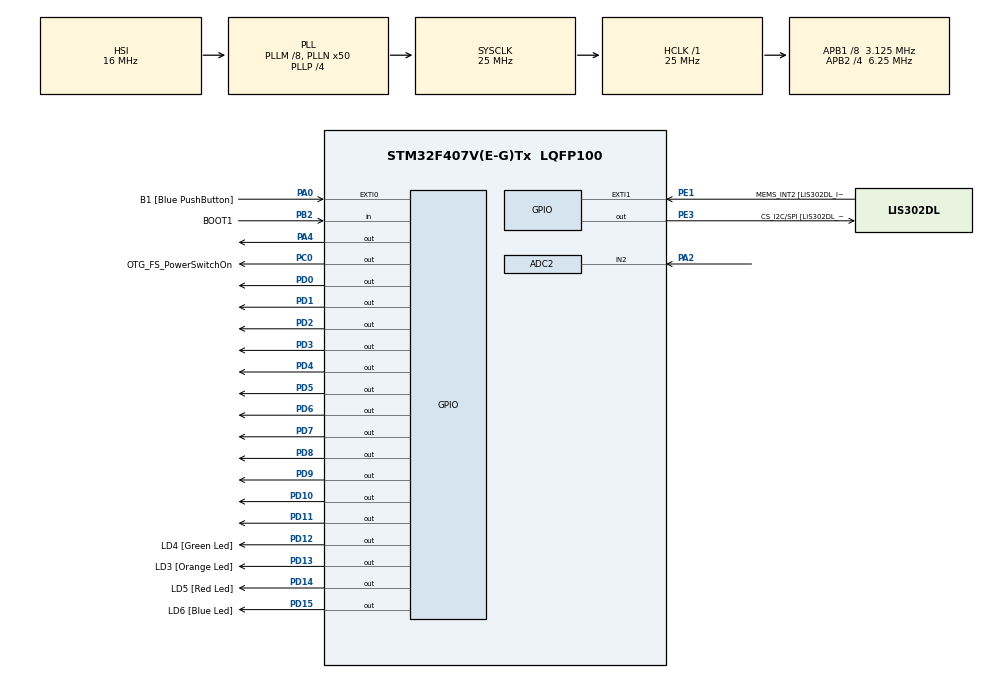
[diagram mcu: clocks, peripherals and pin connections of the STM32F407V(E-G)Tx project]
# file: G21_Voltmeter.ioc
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ADC2.Channel-0\#ChannelRegularConversion=ADC_CHANNEL_2
ADC2.ClockPrescaler=ADC_CLOCK_SYNC_PCLK_DIV2
ADC2.ContinuousConvMode=DISABLE
ADC2.DMAContinuousRequests=DISABLE
ADC2.DataAlign=ADC_DATAALIGN_RIGHT
ADC2.DiscontinuousConvMode=DISABLE
ADC2.EOCSelection=ADC_EOC_SINGLE_CONV
ADC2.EnableAnalogWatchDog=false
ADC2.ExternalTrigConv=ADC_EXTERNALTRIGCONV_T2_TRGO
ADC2.ExternalTrigConvEdge=ADC_EXTERNALTRIGCONVEDGE_RISING
ADC2.InjNumberOfConversion=0
ADC2.NbrOfConversion=1
ADC2.NbrOfConversionFlag=1
ADC2.Rank-0\#ChannelRegularConversion=1
ADC2.Resolution=ADC_RESOLUTION_8B
ADC2.SamplingTime-0\#ChannelRegularConversion=ADC_SAMPLETIME_3CYCLES
ADC2.ScanConvMode=DISABLE
Mcu.Family=STM32F4
Mcu.Name=STM32F407V(E-G)Tx
Mcu.Package=LQFP100
NVIC.ADC_IRQn=true\:0\:0\:false\:false\:true\:true
NVIC.PriorityGroup=NVIC_PRIORITYGROUP_0
NVIC.TIM2_IRQn=true\:0\:0\:false\:false\:true\:true
NVIC.TIM3_IRQn=true\:0\:0\:false\:false\:true\:true
PA0-WKUP.GPIO_Label=B1 [Blue PushButton]
PA0-WKUP.GPIO_ModeDefaultEXTI=GPIO_MODE_EVT_RISING
PA0-WKUP.GPIO_PuPd=GPIO_NOPULL
PA0-WKUP.Signal=GPXTI0
PA10.GPIO_Label=OTG_FS_ID
PA10.GPIO_Mode=GPIO_MODE_AF_PP
PA10.GPIO_PuPd=GPIO_NOPULL
PA10.GPIO_Speed=GPIO_SPEED_FREQ_LOW
PA10.Signal=USB_OTG_FS_ID
PA11.GPIO_Label=OTG_FS_DM
PA11.GPIO_Mode=GPIO_MODE_AF_PP
PA11.GPIO_PuPd=GPIO_NOPULL
PA11.GPIO_Speed=GPIO_SPEED_FREQ_LOW
PA11.Signal=USB_OTG_FS_DM
PA12.GPIO_Label=OTG_FS_DP
PA12.GPIO_Mode=GPIO_MODE_AF_PP
PA12.GPIO_PuPd=GPIO_NOPULL
PA12.GPIO_Speed=GPIO_SPEED_FREQ_LOW
PA12.Signal=USB_OTG_FS_DP
PA13.GPIO_Label=SWDIO
PA13.Signal=SYS_JTMS-SWDIO
PA14.GPIO_Label=SWCLK
PA14.Signal=SYS_JTCK-SWCLK
PA2.Signal=ADCx_IN2
PA4.Signal=GPIO_Output
PA5.GPIO_Label=SPI1_SCK [LIS302DL_SCL/SPC]
PA5.GPIO_Mode=GPIO_MODE_AF_PP
PA5.GPIO_PuPd=GPIO_NOPULL
PA5.GPIO_Speed=GPIO_SPEED_FREQ_LOW
PA5.Signal=SPI1_SCK
PA6.GPIO_Label=SPI1_MISO [LIS302DL_SDO]
PA6.GPIO_Mode=GPIO_MODE_AF_PP
PA6.GPIO_PuPd=GPIO_NOPULL
PA6.GPIO_Speed=GPIO_SPEED_FREQ_LOW
PA6.Signal=SPI1_MISO
PA7.GPIO_Label=SPI1_MOSI [LIS302DL_SDA/SDI/SDO]
PA7.GPIO_Mode=GPIO_MODE_AF_PP
PA7.GPIO_PuPd=GPIO_NOPULL
PA7.GPIO_Speed=GPIO_SPEED_FREQ_LOW
PA7.Signal=SPI1_MOSI
PA9.GPIO_Label=VBUS_FS
PA9.GPIO_Mode=GPIO_MODE_INPUT
PA9.GPIO_PuPd=GPIO_NOPULL
PA9.Signal=USB_OTG_FS_VBUS
PB10.GPIO_Label=CLK_IN [MP45DT02_CLK]
PB10.GPIO_Mode=GPIO_MODE_AF_PP
PB10.GPIO_PuPd=GPIO_NOPULL
PB10.GPIO_Speed=GPIO_SPEED_FREQ_LOW
PB10.Signal=I2S2_CK
PB2.GPIO_Label=BOOT1
PB2.GPIO_Mode=GPIO_MODE_INPUT
PB2.GPIO_PuPd=GPIO_NOPULL
PB2.Signal=GPIO_Input
PB3.GPIO_Label=SWO
PB3.Signal=SYS_JTDO-SWO
PB6.GPIO_Label=Audio_SCL [CS43L22_SCL]
PB6.GPIO_Mode=GPIO_MODE_AF_OD
PB6.GPIO_PuPd=GPIO_NOPULL
PB6.GPIO_Speed=GPIO_SPEED_FREQ_LOW
PB6.Signal=I2C1_SCL
PB9.GPIO_Label=Audio_SDA [CS43L22_SDA]
PB9.GPIO_Mode=GPIO_MODE_AF_OD
PB9.GPIO_PuPd=GPIO_NOPULL
PB9.GPIO_Speed=GPIO_SPEED_FREQ_LOW
PB9.Signal=I2C1_SDA
PC0.GPIO_Label=OTG_FS_PowerSwitchOn
PC0.GPIO_PuPd=GPIO_NOPULL
PC0.GPIO_Speed=GPIO_SPEED_FREQ_LOW
PC0.PinState=GPIO_PIN_SET
PC0.Signal=GPIO_Output
PC10.GPIO_Label=I2S3_SCK [CS43L22_SCLK]
PC10.GPIO_Mode=GPIO_MODE_AF_PP
PC10.GPIO_PuPd=GPIO_NOPULL
PC10.GPIO_Speed=GPIO_SPEED_FREQ_LOW
PC10.Signal=I2S3_CK
PC12.GPIO_Label=I2S3_SD [CS43L22_SDIN]
PC12.GPIO_Mode=GPIO_MODE_AF_PP
PC12.GPIO_PuPd=GPIO_NOPULL
PC12.GPIO_Speed=GPIO_SPEED_FREQ_LOW
PC12.Signal=I2S3_SD
PC14-OSC32_IN.GPIO_Label=PC14-OSC32_IN
PC14-OSC32_IN.Signal=RCC_OSC32_IN
PC15-OSC32_OUT.GPIO_Label=PC15-OSC32_OUT
PC15-OSC32_OUT.Signal=RCC_OSC32_OUT
PC3.GPIO_Label=PDM_OUT [MP45DT02_DOUT]
PC3.GPIO_Mode=GPIO_MODE_AF_PP
PC3.GPIO_PuPd=GPIO_NOPULL
PC3.GPIO_Speed=GPIO_SPEED_FREQ_LOW
PC3.Signal=I2S2_SD
PC7.GPIO_Label=I2S3_MCK [CS43L22_MCLK]
PC7.GPIO_Mode=GPIO_MODE_AF_PP
PC7.GPIO_PuPd=GPIO_NOPULL
PC7.GPIO_Speed=GPIO_SPEED_FREQ_LOW
PC7.Signal=I2S3_MCK
PD0.Signal=GPIO_Output
PD1.Signal=GPIO_Output
PD10.Signal=GPIO_Output
PD11.Signal=GPIO_Output
PD12.GPIO_Label=LD4 [Green Led]
PD12.GPIO_PuPd=GPIO_NOPULL
PD12.GPIO_Speed=GPIO_SPEED_FREQ_LOW
PD12.Signal=GPIO_Output
PD13.GPIO_Label=LD3 [Orange Led]
PD13.GPIO_PuPd=GPIO_NOPULL
PD13.GPIO_Speed=GPIO_SPEED_FREQ_LOW
PD13.Signal=GPIO_Output
PD14.GPIO_Label=LD5 [Red Led]
PD14.GPIO_PuPd=GPIO_NOPULL
PD14.GPIO_Speed=GPIO_SPEED_FREQ_LOW
PD14.Signal=GPIO_Output
PD15.GPIO_Label=LD6 [Blue Led]
PD15.GPIO_PuPd=GPIO_NOPULL
PD15.GPIO_Speed=GPIO_SPEED_FREQ_LOW
PD15.Signal=GPIO_Output
PD2.Signal=GPIO_Output
PD3.Signal=GPIO_Output
PD4.Signal=GPIO_Output
PD5.Signal=GPIO_Output
PD6.Signal=GPIO_Output
PD7.Signal=GPIO_Output
PD8.Signal=GPIO_Output
PD9.Signal=GPIO_Output
PE1.GPIO_Label=MEMS_INT2 [LIS302DL_INT2]
PE1.GPIO_ModeDefaultEXTI=GPIO_MODE_EVT_RISING
PE1.GPIO_PuPd=GPIO_NOPULL
PE1.Signal=GPXTI1
PE3.GPIO_Label=CS_I2C/SPI [LIS302DL_CS_I2C/SPI]
PE3.GPIO_PuPd=GPIO_NOPULL
PE3.GPIO_Speed=GPIO_SPEED_FREQ_LOW
PE3.Signal=GPIO_Output
PH0-OSC_IN.GPIO_Label=PH0-OSC_IN
PH0-OSC_IN.Signal=RCC_OSC_IN
PH1-OSC_OUT.GPIO_Label=PH1-OSC_OUT
PH1-OSC_OUT.Signal=RCC_OSC_OUT
ProjectManager.HeapSize=0x200
ProjectManager.StackSize=0x400
ProjectManager.TargetToolchain=MDK-ARM V5
RCC.48MHZClocksFreq_Value=14285714.285714285
RCC.AHBFreq_Value=25000000
RCC.APB1CLKDivider=RCC_HCLK_DIV8
RCC.APB1Freq_Value=3125000
RCC.APB1TimFreq_Value=6250000
RCC.APB2CLKDivider=RCC_HCLK_DIV4
RCC.APB2Freq_Value=6250000
RCC.APB2TimFreq_Value=12500000
RCC.CortexFreq_Value=25000000
RCC.HCLKFreq_Value=25000000
RCC.HSE_VALUE=8000000
RCC.HSI_VALUE=16000000
RCC.LSE_VALUE=32768
RCC.PLLM=8
RCC.PLLN=50
RCC.PLLP=RCC_PLLP_DIV4
RCC.PLLQ=7
RCC.SYSCLKFreq_VALUE=25000000
RCC.SYSCLKSource=RCC_SYSCLKSOURCE_PLLCLK
RCC.VCOOutputFreq_Value=100000000
SH.ADCx_IN2.0=ADC2_IN2,IN2
TIM2.Period=10
TIM2.Prescaler=625
TIM2.TIM_MasterOutputTrigger=TIM_TRGO_UPDATE
TIM3.Period=100
TIM3.Prescaler=625
TIM3.TIM_MasterOutputTrigger=TIM_TRGO_UPDATE
VP_TIM2_VS_ClockSourceINT.Mode=Internal
VP_TIM3_VS_ClockSourceINT.Mode=Internal
board=STM32F4DISCOVERY

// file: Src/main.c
/**
  ******************************************************************************
  * File Name          : main.c
  * Description        : Main program body
  ******************************************************************************
  ** This notice applies to any and all portions of this file
  * that are not between comment pairs USER CODE BEGIN and
  * USER CODE END. Other portions of this file, whether
  * inserted by the user or by software development tools
  * are owned by their respective copyright owners.
  *
  * COPYRIGHT(c) 2017 STMicroelectronics
  *
  * Redistribution and use in source and binary forms, with or without modification,
  * are permitted provided that the following conditions are met:
  *   1. Redistributions of source code must retain the above copyright notice,
  *      this list of conditions and the following disclaimer.
  *   2. Redistributions in binary form must reproduce the above copyright notice,
  *      this list of conditions and the following disclaimer in the documentation
  *      and/or other materials provided with the distribution.
  *   3. Neither the name of STMicroelectronics nor the names of its contributors
  *      may be used to endorse or promote products derived from this software
  *      without specific prior written permission.
  *
  * THIS SOFTWARE IS PROVIDED BY THE COPYRIGHT HOLDERS AND CONTRIBUTORS "AS IS"
  * AND ANY EXPRESS OR IMPLIED WARRANTIES, INCLUDING, BUT NOT LIMITED TO, THE
  * IMPLIED WARRANTIES OF MERCHANTABILITY AND FITNESS FOR A PARTICULAR PURPOSE ARE
  * DISCLAIMED. IN NO EVENT SHALL THE COPYRIGHT HOLDER OR CONTRIBUTORS BE LIABLE
  * FOR ANY DIRECT, INDIRECT, INCIDENTAL, SPECIAL, EXEMPLARY, OR CONSEQUENTIAL
  * DAMAGES (INCLUDING, BUT NOT LIMITED TO, PROCUREMENT OF SUBSTITUTE GOODS OR
  * SERVICES; LOSS OF USE, DATA, OR PROFITS; OR BUSINESS INTERRUPTION) HOWEVER
  * CAUSED AND ON ANY THEORY OF LIABILITY, WHETHER IN CONTRACT, STRICT LIABILITY,
  * OR TORT (INCLUDING NEGLIGENCE OR OTHERWISE) ARISING IN ANY WAY OUT OF THE USE
  * OF THIS SOFTWARE, EVEN IF ADVISED OF THE POSSIBILITY OF SUCH DAMAGE.
  *
  ******************************************************************************
  */
#include "main.h"
#include "stm32f4xx_hal.h"

/* USER CODE BEGIN Includes */
#include "math.h"
#include "float.h"
/* USER CODE END Includes */

ADC_HandleTypeDef hadc2;

TIM_HandleTypeDef htim2;
TIM_HandleTypeDef htim3;

/* USER CODE BEGIN PV */
/* Private variables ---------------------------------------------------------*/

/* USER CODE END PV */

void SystemClock_Config(void);
static void MX_GPIO_Init(void);
static void MX_ADC2_Init(void);
static void MX_TIM3_Init(void);
static void MX_TIM2_Init(void);

/* USER CODE BEGIN PFP */
/* Private function prototypes -----------------------------------------------*/
void numControl(int num, int D);
void FloatToIntArr(float num);
/* USER CODE END PFP */

/* USER CODE GLOBAL VARs */
const int N = 10;	//window size
const float SYS_VOLT = 2.98;	//system voltage
const int COUNT_MAX = 1;	//delay in displaying

float valA = 0, valB = 0;
unsigned int adcVal;	//stores sample form ADC
float volt;	//stores voltage conversion
float Vrms;	//stores Vrms value
int counter;//to generate a square wave of 1/counter Hz
int k = 1;	//before N samples
int D[4];		//stores numbers to be displayed
float buff[N];//stores inst voltages
/* USER CODE END GLOBAL VARs */

int main(void)
{

  /* MCU Configuration----------------------------------------------------------*/

  /* Reset of all peripherals, Initializes the Flash interface and the Systick. */
  HAL_Init();

  /* Configure the system clock */
  SystemClock_Config();

  /* Initialize all configured peripherals */
  MX_GPIO_Init();
  MX_ADC2_Init();
  MX_TIM3_Init();
  MX_TIM2_Init();

	/* Start Timer as interrupt */
	HAL_TIM_Base_Start_IT(&htim2);
	HAL_TIM_Base_Start_IT(&htim3);

	/* Start ADC */
	HAL_ADC_Start(&hadc2);

	/* USER CODE 7-SEGMENT DISPLAY */

	/*---PIN CONFIGURATION---
	GPIO_PIN_11 (PD11) <- D4 SET
	GPIO_PIN_10 (PD10) <- D3 SET
	GPIO_PIN_9 (PD9) <- D2  SET
	GPIO_PIN_8 (PD8) <- D1 SET

	GPIO_PIN_0 (PD0) <- A
	GPIO_PIN_1 (PD1) <- B
	GPIO_PIN_2 (PD2) <- C
	GPIO_PIN_3 (PD3) <- D
	GPIO_PIN_4 (PD4) <- E
	GPIO_PIN_5 (PD5) <- F
	GPIO_PIN_6 (PD6) <- G
	GPIO_PIN_7 (PD7) <- DP
	*/
  while (1)
  {
		/* converts from float to int[]
			 D[0] <- num in D1
			 D[1] <- num in D2
			 D[2] <- num in D3
			 D[3] <- num in D4
		*/

		FloatToIntArr(Vrms);

		while(counter != COUNT_MAX) {
			for(int i = 0; i < 4; i++) {	//Display
				numControl(D[i], i);
				HAL_Delay(1);
			}
			if(counter > COUNT_MAX) counter = 0;
		}

  }

	/* USER CODE END */

}

/* ISR HANDLER(EVERY 1ms) DO:
	 1. ADC sample
	 2. Overhead(conversion+updating+calculation)
	 3. checks*/
void HAL_TIM_PeriodElapsedCallback(TIM_HandleTypeDef *htim) {
	if(htim == &htim2) {	//ADC sampling
		/*
		range: 0 to 255 (8 bits)
		Sysyem voltage = 2.98V

		Measured voltage = (System voltage * adcVal)/255
		*/

		adcVal = HAL_ADC_GetValue(&hadc2);	//take a sample

		//convert ADC to Voltage
		volt = (adcVal*SYS_VOLT)/255;

		//update valA and valB
		valA += volt*volt;
		valB += (buff[0]*buff[0]);

		if(valA > FLT_MAX-20){	//overflow handler
			valA = valA-valB;
			valB = 0;
		}

		if(k < N) {	//takes care or first N samples
			Vrms = sqrt(valA/k);
			k++;
		} else {
			Vrms = sqrt((valA-valB)/N);
		}

		//update buffer
		for(int i = 0; i < N-1; i++) {
			buff[i] = buff[i+1];
		}
		buff[N-1] = volt;
	}

	else if(htim == &htim3) {	//AC square signal(50Hz)
		counter++;
		HAL_GPIO_TogglePin(GPIOA, GPIO_PIN_4);
	}

}

/* USER HELPER FUNCTIONS*/

/* Sets a digit (of the 7-segment display),
	 and the corresponding segments */
void numControl(int num, int D) {
	/* Truth table of numbers 0-9
			NUM		A	B	C	D	E	F	G

				0		1	1	1	1	1	1	0

				1		0	1	1	0	0	0	0

				2		1	1	0	1	1	0	1

				3		1	1	1	1	0	0	1

				4		0	1	1	0	0	1	1

				5		1	0	1	1	0	1	1

				6		1	0	1	1	1	1	1

				7		1	1	1	0	0	0	0

				8		1	1	1	1	1	1	1

				9		1	1	1	1	0	1	1
	*/

	/*takes care of setting/resetting Ds
	  decimal point is set with D2 */
	if(D == 0) {
		HAL_GPIO_WritePin(GPIOD, GPIO_PIN_7, GPIO_PIN_RESET);
		HAL_GPIO_WritePin(GPIOD, GPIO_PIN_8, GPIO_PIN_RESET);
		HAL_GPIO_WritePin(GPIOD, GPIO_PIN_9, GPIO_PIN_RESET);
		HAL_GPIO_WritePin(GPIOD, GPIO_PIN_10, GPIO_PIN_RESET);
		HAL_GPIO_WritePin(GPIOD, GPIO_PIN_11, GPIO_PIN_RESET);
	}
	else if(D == 1) {
		HAL_GPIO_WritePin(GPIOD, GPIO_PIN_7, GPIO_PIN_SET);
		HAL_GPIO_WritePin(GPIOD, GPIO_PIN_8, GPIO_PIN_RESET);
		HAL_GPIO_WritePin(GPIOD, GPIO_PIN_9, GPIO_PIN_SET);
		HAL_GPIO_WritePin(GPIOD, GPIO_PIN_10, GPIO_PIN_RESET);
		HAL_GPIO_WritePin(GPIOD, GPIO_PIN_11, GPIO_PIN_RESET);
	}
	else if(D == 2) {
		HAL_GPIO_WritePin(GPIOD, GPIO_PIN_7, GPIO_PIN_RESET);
		HAL_GPIO_WritePin(GPIOD, GPIO_PIN_8, GPIO_PIN_RESET);
		HAL_GPIO_WritePin(GPIOD, GPIO_PIN_9, GPIO_PIN_RESET);
		HAL_GPIO_WritePin(GPIOD, GPIO_PIN_10, GPIO_PIN_SET);
		HAL_GPIO_WritePin(GPIOD, GPIO_PIN_11, GPIO_PIN_RESET);
	}
	else if(D == 3) {
		HAL_GPIO_WritePin(GPIOD, GPIO_PIN_7, GPIO_PIN_RESET);
		HAL_GPIO_WritePin(GPIOD, GPIO_PIN_8, GPIO_PIN_RESET);
		HAL_GPIO_WritePin(GPIOD, GPIO_PIN_9, GPIO_PIN_RESET);
		HAL_GPIO_WritePin(GPIOD, GPIO_PIN_10, GPIO_PIN_RESET);
		HAL_GPIO_WritePin(GPIOD, GPIO_PIN_11, GPIO_PIN_SET);
	}

	//takes care of displaying the required number (according to the truth table)
	if(num == 0) {
		HAL_GPIO_WritePin(GPIOD, GPIO_PIN_0, GPIO_PIN_SET);
		HAL_GPIO_WritePin(GPIOD, GPIO_PIN_1, GPIO_PIN_SET);
		HAL_GPIO_WritePin(GPIOD, GPIO_PIN_2, GPIO_PIN_SET);
		HAL_GPIO_WritePin(GPIOD, GPIO_PIN_3, GPIO_PIN_SET);
		HAL_GPIO_WritePin(GPIOD, GPIO_PIN_4, GPIO_PIN_SET);
		HAL_GPIO_WritePin(GPIOD, GPIO_PIN_5, GPIO_PIN_SET);
		HAL_GPIO_WritePin(GPIOD, GPIO_PIN_6, GPIO_PIN_RESET);
	} else if(num == 1) {
		HAL_GPIO_WritePin(GPIOD, GPIO_PIN_0, GPIO_PIN_RESET);
		HAL_GPIO_WritePin(GPIOD, GPIO_PIN_1, GPIO_PIN_SET);
		HAL_GPIO_WritePin(GPIOD, GPIO_PIN_2, GPIO_PIN_SET);
		HAL_GPIO_WritePin(GPIOD, GPIO_PIN_3, GPIO_PIN_RESET);
		HAL_GPIO_WritePin(GPIOD, GPIO_PIN_4, GPIO_PIN_RESET);
		HAL_GPIO_WritePin(GPIOD, GPIO_PIN_5, GPIO_PIN_RESET);
		HAL_GPIO_WritePin(GPIOD, GPIO_PIN_6, GPIO_PIN_RESET);
	} else if(num == 2) {
		HAL_GPIO_WritePin(GPIOD, GPIO_PIN_0, GPIO_PIN_SET);
		HAL_GPIO_WritePin(GPIOD, GPIO_PIN_1, GPIO_PIN_SET);
		HAL_GPIO_WritePin(GPIOD, GPIO_PIN_2, GPIO_PIN_RESET);
		HAL_GPIO_WritePin(GPIOD, GPIO_PIN_3, GPIO_PIN_SET);
		HAL_GPIO_WritePin(GPIOD, GPIO_PIN_4, GPIO_PIN_SET);
		HAL_GPIO_WritePin(GPIOD, GPIO_PIN_5, GPIO_PIN_RESET);
		HAL_GPIO_WritePin(GPIOD, GPIO_PIN_6, GPIO_PIN_SET);
	} else if(num == 3) {
		HAL_GPIO_WritePin(GPIOD, GPIO_PIN_0, GPIO_PIN_SET);
		HAL_GPIO_WritePin(GPIOD, GPIO_PIN_1, GPIO_PIN_SET);
		HAL_GPIO_WritePin(GPIOD, GPIO_PIN_2, GPIO_PIN_SET);
		HAL_GPIO_WritePin(GPIOD, GPIO_PIN_3, GPIO_PIN_SET);
		HAL_GPIO_WritePin(GPIOD, GPIO_PIN_4, GPIO_PIN_RESET);
		HAL_GPIO_WritePin(GPIOD, GPIO_PIN_5, GPIO_PIN_RESET);
		HAL_GPIO_WritePin(GPIOD, GPIO_PIN_6, GPIO_PIN_SET);
	} else if(num == 4) {
		HAL_GPIO_WritePin(GPIOD, GPIO_PIN_0, GPIO_PIN_RESET);
		HAL_GPIO_WritePin(GPIOD, GPIO_PIN_1, GPIO_PIN_SET);
		HAL_GPIO_WritePin(GPIOD, GPIO_PIN_2, GPIO_PIN_SET);
		HAL_GPIO_WritePin(GPIOD, GPIO_PIN_3, GPIO_PIN_RESET);
		HAL_GPIO_WritePin(GPIOD, GPIO_PIN_4, GPIO_PIN_RESET);
		HAL_GPIO_WritePin(GPIOD, GPIO_PIN_5, GPIO_PIN_SET);
		HAL_GPIO_WritePin(GPIOD, GPIO_PIN_6, GPIO_PIN_SET);
	} else if(num == 5) {
		HAL_GPIO_WritePin(GPIOD, GPIO_PIN_0, GPIO_PIN_SET);
		HAL_GPIO_WritePin(GPIOD, GPIO_PIN_1, GPIO_PIN_RESET);
		HAL_GPIO_WritePin(GPIOD, GPIO_PIN_2, GPIO_PIN_SET);
		HAL_GPIO_WritePin(GPIOD, GPIO_PIN_3, GPIO_PIN_SET);
		HAL_GPIO_WritePin(GPIOD, GPIO_PIN_4, GPIO_PIN_RESET);
		HAL_GPIO_WritePin(GPIOD, GPIO_PIN_5, GPIO_PIN_SET);
		HAL_GPIO_WritePin(GPIOD, GPIO_PIN_6, GPIO_PIN_SET);
	} else if(num == 6) {
		HAL_GPIO_WritePin(GPIOD, GPIO_PIN_0, GPIO_PIN_SET);
		HAL_GPIO_WritePin(GPIOD, GPIO_PIN_1, GPIO_PIN_RESET);
		HAL_GPIO_WritePin(GPIOD, GPIO_PIN_2, GPIO_PIN_SET);
		HAL_GPIO_WritePin(GPIOD, GPIO_PIN_3, GPIO_PIN_SET);
		HAL_GPIO_WritePin(GPIOD, GPIO_PIN_4, GPIO_PIN_SET);
		HAL_GPIO_WritePin(GPIOD, GPIO_PIN_5, GPIO_PIN_SET);
		HAL_GPIO_WritePin(GPIOD, GPIO_PIN_6, GPIO_PIN_SET);
	} else if(num == 7) {
		HAL_GPIO_WritePin(GPIOD, GPIO_PIN_0, GPIO_PIN_SET);
		HAL_GPIO_WritePin(GPIOD, GPIO_PIN_1, GPIO_PIN_SET);
		HAL_GPIO_WritePin(GPIOD, GPIO_PIN_2, GPIO_PIN_SET);
		HAL_GPIO_WritePin(GPIOD, GPIO_PIN_3, GPIO_PIN_RESET);
		HAL_GPIO_WritePin(GPIOD, GPIO_PIN_4, GPIO_PIN_RESET);
		HAL_GPIO_WritePin(GPIOD, GPIO_PIN_5, GPIO_PIN_RESET);
		HAL_GPIO_WritePin(GPIOD, GPIO_PIN_6, GPIO_PIN_RESET);
	} else if(num == 8) {
		HAL_GPIO_WritePin(GPIOD, GPIO_PIN_0, GPIO_PIN_SET);
		HAL_GPIO_WritePin(GPIOD, GPIO_PIN_1, GPIO_PIN_SET);
		HAL_GPIO_WritePin(GPIOD, GPIO_PIN_2, GPIO_PIN_SET);
		HAL_GPIO_WritePin(GPIOD, GPIO_PIN_3, GPIO_PIN_SET);
		HAL_GPIO_WritePin(GPIOD, GPIO_PIN_4, GPIO_PIN_SET);
		HAL_GPIO_WritePin(GPIOD, GPIO_PIN_5, GPIO_PIN_SET);
		HAL_GPIO_WritePin(GPIOD, GPIO_PIN_6, GPIO_PIN_SET);
	} else if(num == 9) {
		HAL_GPIO_WritePin(GPIOD, GPIO_PIN_0, GPIO_PIN_SET);
		HAL_GPIO_WritePin(GPIOD, GPIO_PIN_1, GPIO_PIN_SET);
		HAL_GPIO_WritePin(GPIOD, GPIO_PIN_2, GPIO_PIN_SET);
		HAL_GPIO_WritePin(GPIOD, GPIO_PIN_3, GPIO_PIN_SET);
		HAL_GPIO_WritePin(GPIOD, GPIO_PIN_4, GPIO_PIN_RESET);
		HAL_GPIO_WritePin(GPIOD, GPIO_PIN_5, GPIO_PIN_SET);
		HAL_GPIO_WritePin(GPIOD, GPIO_PIN_6, GPIO_PIN_SET);
	}

}

/* converts from float to int[]
	 D[0] <- num in D1
	 D[1] <- num in D2
	 D[2] <- num in D3
	 D[3] <- num in D4*/
void FloatToIntArr(float num) {
	D[0] = (int)(num/10);
	D[1] = (int)num - D[0]*10;
	D[2] = (int)(num*10) - D[1]*10 - D[0]*100;
	D[3] = (int)(num*100) - D[2]*10 - D[1]*100 - D[0]*1000;

}

/* USER HELPER FUNCTIONS END*/

/** System Clock Configuration
*/
void SystemClock_Config(void)
{

  RCC_OscInitTypeDef RCC_OscInitStruct;
  RCC_ClkInitTypeDef RCC_ClkInitStruct;

    /**Configure the main internal regulator output voltage
    */
  __HAL_RCC_PWR_CLK_ENABLE();

  __HAL_PWR_VOLTAGESCALING_CONFIG(PWR_REGULATOR_VOLTAGE_SCALE1);

    /**Initializes the CPU, AHB and APB busses clocks
    */
  RCC_OscInitStruct.OscillatorType = RCC_OSCILLATORTYPE_HSI;
  RCC_OscInitStruct.HSIState = RCC_HSI_ON;
  RCC_OscInitStruct.HSICalibrationValue = 16;
  RCC_OscInitStruct.PLL.PLLState = RCC_PLL_ON;
  RCC_OscInitStruct.PLL.PLLSource = RCC_PLLSOURCE_HSI;
  RCC_OscInitStruct.PLL.PLLM = 8;
  RCC_OscInitStruct.PLL.PLLN = 50;
  RCC_OscInitStruct.PLL.PLLP = RCC_PLLP_DIV4;
  RCC_OscInitStruct.PLL.PLLQ = 7;
  if (HAL_RCC_OscConfig(&RCC_OscInitStruct) != HAL_OK)
  {
    _Error_Handler(__FILE__, __LINE__);
  }

    /**Initializes the CPU, AHB and APB busses clocks
    */
  RCC_ClkInitStruct.ClockType = RCC_CLOCKTYPE_HCLK|RCC_CLOCKTYPE_SYSCLK
                              |RCC_CLOCKTYPE_PCLK1|RCC_CLOCKTYPE_PCLK2;
  RCC_ClkInitStruct.SYSCLKSource = RCC_SYSCLKSOURCE_PLLCLK;
  RCC_ClkInitStruct.AHBCLKDivider = RCC_SYSCLK_DIV1;
  RCC_ClkInitStruct.APB1CLKDivider = RCC_HCLK_DIV8;
  RCC_ClkInitStruct.APB2CLKDivider = RCC_HCLK_DIV4;

  if (HAL_RCC_ClockConfig(&RCC_ClkInitStruct, FLASH_LATENCY_0) != HAL_OK)
  {
    _Error_Handler(__FILE__, __LINE__);
  }

    /**Configure the Systick interrupt time
    */
  HAL_SYSTICK_Config(HAL_RCC_GetHCLKFreq()/1000);

    /**Configure the Systick
    */
  HAL_SYSTICK_CLKSourceConfig(SYSTICK_CLKSOURCE_HCLK);

  /* SysTick_IRQn interrupt configuration */
  HAL_NVIC_SetPriority(SysTick_IRQn, 0, 0);
}

/* ADC2 init function */
static void MX_ADC2_Init(void)
{

  ADC_ChannelConfTypeDef sConfig;

    /**Configure the global features of the ADC (Clock, Resolution, Data Alignment and number of conversion)
    */
  hadc2.Instance = ADC2;
  hadc2.Init.ClockPrescaler = ADC_CLOCK_SYNC_PCLK_DIV2;
  hadc2.Init.Resolution = ADC_RESOLUTION_8B;
  hadc2.Init.ScanConvMode = DISABLE;
  hadc2.Init.ContinuousConvMode = DISABLE;
  hadc2.Init.DiscontinuousConvMode = DISABLE;
  hadc2.Init.ExternalTrigConvEdge = ADC_EXTERNALTRIGCONVEDGE_RISING;
  hadc2.Init.ExternalTrigConv = ADC_EXTERNALTRIGCONV_T2_TRGO;
  hadc2.Init.DataAlign = ADC_DATAALIGN_RIGHT;
  hadc2.Init.NbrOfConversion = 1;
  hadc2.Init.DMAContinuousRequests = DISABLE;
  hadc2.Init.EOCSelection = ADC_EOC_SINGLE_CONV;
  if (HAL_ADC_Init(&hadc2) != HAL_OK)
  {
    _Error_Handler(__FILE__, __LINE__);
  }

    /**Configure for the selected ADC regular channel its corresponding rank in the sequencer and its sample time.
    */
  sConfig.Channel = ADC_CHANNEL_2;
  sConfig.Rank = 1;
  sConfig.SamplingTime = ADC_SAMPLETIME_3CYCLES;
  if (HAL_ADC_ConfigChannel(&hadc2, &sConfig) != HAL_OK)
  {
    _Error_Handler(__FILE__, __LINE__);
  }

}

/* TIM2 init function */
static void MX_TIM2_Init(void)
{

  TIM_ClockConfigTypeDef sClockSourceConfig;
  TIM_MasterConfigTypeDef sMasterConfig;

  htim2.Instance = TIM2;
  htim2.Init.Prescaler = 625;
  htim2.Init.CounterMode = TIM_COUNTERMODE_UP;
  htim2.Init.Period = 100;
  htim2.Init.ClockDivision = TIM_CLOCKDIVISION_DIV1;
  if (HAL_TIM_Base_Init(&htim2) != HAL_OK)
  {
    _Error_Handler(__FILE__, __LINE__);
  }

  sClockSourceConfig.ClockSource = TIM_CLOCKSOURCE_INTERNAL;
  if (HAL_TIM_ConfigClockSource(&htim2, &sClockSourceConfig) != HAL_OK)
  {
    _Error_Handler(__FILE__, __LINE__);
  }

  sMasterConfig.MasterOutputTrigger = TIM_TRGO_UPDATE;
  sMasterConfig.MasterSlaveMode = TIM_MASTERSLAVEMODE_DISABLE;
  if (HAL_TIMEx_MasterConfigSynchronization(&htim2, &sMasterConfig) != HAL_OK)
  {
    _Error_Handler(__FILE__, __LINE__);
  }

}

/* TIM3 init function */
static void MX_TIM3_Init(void)
{

  TIM_ClockConfigTypeDef sClockSourceConfig;
  TIM_MasterConfigTypeDef sMasterConfig;

  htim3.Instance = TIM3;
  htim3.Init.Prescaler = 625;
  htim3.Init.CounterMode = TIM_COUNTERMODE_UP;
  htim3.Init.Period = 100;
  htim3.Init.ClockDivision = TIM_CLOCKDIVISION_DIV1;
  if (HAL_TIM_Base_Init(&htim3) != HAL_OK)
  {
    _Error_Handler(__FILE__, __LINE__);
  }

  sClockSourceConfig.ClockSource = TIM_CLOCKSOURCE_INTERNAL;
  if (HAL_TIM_ConfigClockSource(&htim3, &sClockSourceConfig) != HAL_OK)
  {
    _Error_Handler(__FILE__, __LINE__);
  }

  sMasterConfig.MasterOutputTrigger = TIM_TRGO_UPDATE;
  sMasterConfig.MasterSlaveMode = TIM_MASTERSLAVEMODE_DISABLE;
  if (HAL_TIMEx_MasterConfigSynchronization(&htim3, &sMasterConfig) != HAL_OK)
  {
    _Error_Handler(__FILE__, __LINE__);
  }

}

/** Configure pins as
        * Analog
        * Input
        * Output
        * EVENT_OUT
        * EXTI
     PC3   ------> I2S2_SD
     PA5   ------> SPI1_SCK
     PA6   ------> SPI1_MISO
     PA7   ------> SPI1_MOSI
     PB10   ------> I2S2_CK
     PC7   ------> I2S3_MCK
     PA9   ------> USB_OTG_FS_VBUS
     PA10   ------> USB_OTG_FS_ID
     PA11   ------> USB_OTG_FS_DM
     PA12   ------> USB_OTG_FS_DP
     PC10   ------> I2S3_CK
     PC12   ------> I2S3_SD
     PB6   ------> I2C1_SCL
     PB9   ------> I2C1_SDA
*/
static void MX_GPIO_Init(void)
{

  GPIO_InitTypeDef GPIO_InitStruct;

  /* GPIO Ports Clock Enable */
  __HAL_RCC_GPIOE_CLK_ENABLE();
  __HAL_RCC_GPIOC_CLK_ENABLE();
  __HAL_RCC_GPIOH_CLK_ENABLE();
  __HAL_RCC_GPIOA_CLK_ENABLE();
  __HAL_RCC_GPIOB_CLK_ENABLE();
  __HAL_RCC_GPIOD_CLK_ENABLE();

  /*Configure GPIO pin Output Level */
  HAL_GPIO_WritePin(CS_I2C_SPI_GPIO_Port, CS_I2C_SPI_Pin, GPIO_PIN_RESET);

  /*Configure GPIO pin Output Level */
  HAL_GPIO_WritePin(OTG_FS_PowerSwitchOn_GPIO_Port, OTG_FS_PowerSwitchOn_Pin, GPIO_PIN_SET);

  /*Configure GPIO pin Output Level */
  HAL_GPIO_WritePin(GPIOA, GPIO_PIN_4, GPIO_PIN_RESET);

  /*Configure GPIO pin Output Level */
  HAL_GPIO_WritePin(GPIOD, GPIO_PIN_8|GPIO_PIN_9|GPIO_PIN_10|GPIO_PIN_11
                          |LD4_Pin|LD3_Pin|LD5_Pin|LD6_Pin
                          |GPIO_PIN_0|GPIO_PIN_1|GPIO_PIN_2|GPIO_PIN_3
                          |GPIO_PIN_4|GPIO_PIN_5|GPIO_PIN_6|GPIO_PIN_7, GPIO_PIN_RESET);

  /*Configure GPIO pin : CS_I2C_SPI_Pin */
  GPIO_InitStruct.Pin = CS_I2C_SPI_Pin;
  GPIO_InitStruct.Mode = GPIO_MODE_OUTPUT_PP;
  GPIO_InitStruct.Pull = GPIO_NOPULL;
  GPIO_InitStruct.Speed = GPIO_SPEED_FREQ_LOW;
  HAL_GPIO_Init(CS_I2C_SPI_GPIO_Port, &GPIO_InitStruct);

  /*Configure GPIO pin : OTG_FS_PowerSwitchOn_Pin */
  GPIO_InitStruct.Pin = OTG_FS_PowerSwitchOn_Pin;
  GPIO_InitStruct.Mode = GPIO_MODE_OUTPUT_PP;
  GPIO_InitStruct.Pull = GPIO_NOPULL;
  GPIO_InitStruct.Speed = GPIO_SPEED_FREQ_LOW;
  HAL_GPIO_Init(OTG_FS_PowerSwitchOn_GPIO_Port, &GPIO_InitStruct);

  /*Configure GPIO pin : PDM_OUT_Pin */
  GPIO_InitStruct.Pin = PDM_OUT_Pin;
  GPIO_InitStruct.Mode = GPIO_MODE_AF_PP;
  GPIO_InitStruct.Pull = GPIO_NOPULL;
  GPIO_InitStruct.Speed = GPIO_SPEED_FREQ_LOW;
  GPIO_InitStruct.Alternate = GPIO_AF5_SPI2;
  HAL_GPIO_Init(PDM_OUT_GPIO_Port, &GPIO_InitStruct);

  /*Configure GPIO pin : B1_Pin */
  GPIO_InitStruct.Pin = B1_Pin;
  GPIO_InitStruct.Mode = GPIO_MODE_EVT_RISING;
  GPIO_InitStruct.Pull = GPIO_NOPULL;
  HAL_GPIO_Init(B1_GPIO_Port, &GPIO_InitStruct);

  /*Configure GPIO pin : PA4 */
  GPIO_InitStruct.Pin = GPIO_PIN_4;
  GPIO_InitStruct.Mode = GPIO_MODE_OUTPUT_PP;
  GPIO_InitStruct.Pull = GPIO_NOPULL;
  GPIO_InitStruct.Speed = GPIO_SPEED_FREQ_LOW;
  HAL_GPIO_Init(GPIOA, &GPIO_InitStruct);

  /*Configure GPIO pins : SPI1_SCK_Pin SPI1_MISO_Pin SPI1_MOSI_Pin */
  GPIO_InitStruct.Pin = SPI1_SCK_Pin|SPI1_MISO_Pin|SPI1_MOSI_Pin;
  GPIO_InitStruct.Mode = GPIO_MODE_AF_PP;
  GPIO_InitStruct.Pull = GPIO_NOPULL;
  GPIO_InitStruct.Speed = GPIO_SPEED_FREQ_LOW;
  GPIO_InitStruct.Alternate = GPIO_AF5_SPI1;
  HAL_GPIO_Init(GPIOA, &GPIO_InitStruct);

  /*Configure GPIO pin : BOOT1_Pin */
  GPIO_InitStruct.Pin = BOOT1_Pin;
  GPIO_InitStruct.Mode = GPIO_MODE_INPUT;
  GPIO_InitStruct.Pull = GPIO_NOPULL;
  HAL_GPIO_Init(BOOT1_GPIO_Port, &GPIO_InitStruct);

  /*Configure GPIO pin : CLK_IN_Pin */
  GPIO_InitStruct.Pin = CLK_IN_Pin;
  GPIO_InitStruct.Mode = GPIO_MODE_AF_PP;
  GPIO_InitStruct.Pull = GPIO_NOPULL;
  GPIO_InitStruct.Speed = GPIO_SPEED_FREQ_LOW;
  GPIO_InitStruct.Alternate = GPIO_AF5_SPI2;
  HAL_GPIO_Init(CLK_IN_GPIO_Port, &GPIO_InitStruct);

  /*Configure GPIO pins : PD8 PD9 PD10 PD11
                           LD4_Pin LD3_Pin LD5_Pin LD6_Pin
                           PD0 PD1 PD2 PD3
                           PD4 PD5 PD6 PD7 */
  GPIO_InitStruct.Pin = GPIO_PIN_8|GPIO_PIN_9|GPIO_PIN_10|GPIO_PIN_11
                          |LD4_Pin|LD3_Pin|LD5_Pin|LD6_Pin
                          |GPIO_PIN_0|GPIO_PIN_1|GPIO_PIN_2|GPIO_PIN_3
                          |GPIO_PIN_4|GPIO_PIN_5|GPIO_PIN_6|GPIO_PIN_7;
  GPIO_InitStruct.Mode = GPIO_MODE_OUTPUT_PP;
  GPIO_InitStruct.Pull = GPIO_NOPULL;
  GPIO_InitStruct.Speed = GPIO_SPEED_FREQ_LOW;
  HAL_GPIO_Init(GPIOD, &GPIO_InitStruct);

  /*Configure GPIO pins : I2S3_MCK_Pin I2S3_SCK_Pin I2S3_SD_Pin */
  GPIO_InitStruct.Pin = I2S3_MCK_Pin|I2S3_SCK_Pin|I2S3_SD_Pin;
  GPIO_InitStruct.Mode = GPIO_MODE_AF_PP;
  GPIO_InitStruct.Pull = GPIO_NOPULL;
  GPIO_InitStruct.Speed = GPIO_SPEED_FREQ_LOW;
  GPIO_InitStruct.Alternate = GPIO_AF6_SPI3;
  HAL_GPIO_Init(GPIOC, &GPIO_InitStruct);

  /*Configure GPIO pin : VBUS_FS_Pin */
  GPIO_InitStruct.Pin = VBUS_FS_Pin;
  GPIO_InitStruct.Mode = GPIO_MODE_INPUT;
  GPIO_InitStruct.Pull = GPIO_NOPULL;
  HAL_GPIO_Init(VBUS_FS_GPIO_Port, &GPIO_InitStruct);

  /*Configure GPIO pins : OTG_FS_ID_Pin OTG_FS_DM_Pin OTG_FS_DP_Pin */
  GPIO_InitStruct.Pin = OTG_FS_ID_Pin|OTG_FS_DM_Pin|OTG_FS_DP_Pin;
  GPIO_InitStruct.Mode = GPIO_MODE_AF_PP;
  GPIO_InitStruct.Pull = GPIO_NOPULL;
  GPIO_InitStruct.Speed = GPIO_SPEED_FREQ_LOW;
  GPIO_InitStruct.Alternate = GPIO_AF10_OTG_FS;
  HAL_GPIO_Init(GPIOA, &GPIO_InitStruct);

  /*Configure GPIO pins : Audio_SCL_Pin Audio_SDA_Pin */
  GPIO_InitStruct.Pin = Audio_SCL_Pin|Audio_SDA_Pin;
  GPIO_InitStruct.Mode = GPIO_MODE_AF_OD;
  GPIO_InitStruct.Pull = GPIO_PULLUP;
  GPIO_InitStruct.Speed = GPIO_SPEED_FREQ_LOW;
  GPIO_InitStruct.Alternate = GPIO_AF4_I2C1;
  HAL_GPIO_Init(GPIOB, &GPIO_InitStruct);

  /*Configure GPIO pin : MEMS_INT2_Pin */
  GPIO_InitStruct.Pin = MEMS_INT2_Pin;
  GPIO_InitStruct.Mode = GPIO_MODE_EVT_RISING;
  GPIO_InitStruct.Pull = GPIO_NOPULL;
  HAL_GPIO_Init(MEMS_INT2_GPIO_Port, &GPIO_InitStruct);

}

void _Error_Handler(char * file, int line)
{
  while(1)
  {
  }
}

/************************ (C) COPYRIGHT STMicroelectronics *****END OF FILE****/
